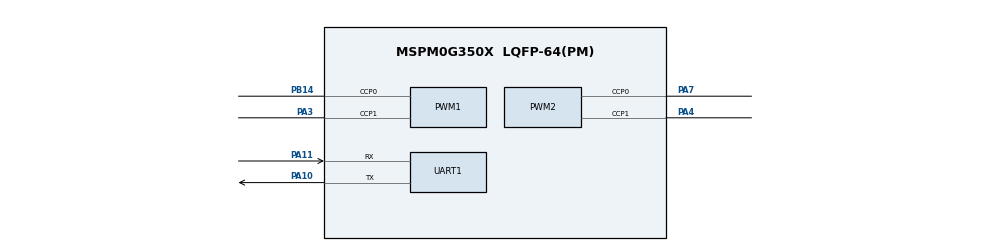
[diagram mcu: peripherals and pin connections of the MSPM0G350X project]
/**
 * @cliArgs --device "MSPM0G350X" --package "LQFP-64(PM)" --part "Default" --product "mspm0_sdk@2.01.00.03"
 * @versions {"tool":"1.20.0+3587"}
 */

/**
 * Import the modules used in this configuration.
 */
const Board         = scripting.addModule("/ti/driverlib/Board");
const GPIO          = scripting.addModule("/ti/driverlib/GPIO", {}, false);
const GPIO1         = GPIO.addInstance();
const GPIO2         = GPIO.addInstance();
const PWM           = scripting.addModule("/ti/driverlib/PWM", {}, false);
const PWM1          = PWM.addInstance();
const PWM2          = PWM.addInstance();
const SYSCTL        = scripting.addModule("/ti/driverlib/SYSCTL");
const TIMER         = scripting.addModule("/ti/driverlib/TIMER", {}, false);
const TIMER1        = TIMER.addInstance();
const UART          = scripting.addModule("/ti/driverlib/UART", {}, false);
const UART1         = UART.addInstance();
const ProjectConfig = scripting.addModule("/ti/project_config/ProjectConfig");

/**
 * Write custom configuration values to the imported modules.
 */

GPIO1.$name                          = "PCA9555";
GPIO1.associatedPins.create(2);
GPIO1.associatedPins[0].assignedPort = "PORTA";
GPIO1.associatedPins[0].assignedPin  = "0";
GPIO1.associatedPins[0].$name        = "SCL1";
GPIO1.associatedPins[1].assignedPort = "PORTA";
GPIO1.associatedPins[1].assignedPin  = "1";
GPIO1.associatedPins[1].$name        = "SDA1";

GPIO2.$name                          = "OLED";
GPIO2.associatedPins.create(2);
GPIO2.associatedPins[0].$name        = "SCL2";
GPIO2.associatedPins[0].assignedPort = "PORTB";
GPIO2.associatedPins[0].assignedPin  = "2";
GPIO2.associatedPins[1].$name        = "SDA2";
GPIO2.associatedPins[1].assignedPort = "PORTB";
GPIO2.associatedPins[1].assignedPin  = "3";

PWM1.$name                              = "Motor_PWM1";
PWM1.timerStartTimer                    = true;
PWM1.pwmMode                            = "EDGE_ALIGN_UP";
PWM1.timerCount                         = 3000;
PWM1.clockDivider                       = 8;
PWM1.peripheral.$assign                 = "TIMA0";
PWM1.peripheral.ccp0Pin.$assign         = "PB14";
PWM1.peripheral.ccp1Pin.$assign         = "PA3";
PWM1.PWM_CHANNEL_0.$name                = "ti_driverlib_pwm_PWMTimerCC0";
PWM1.PWM_CHANNEL_1.$name                = "ti_driverlib_pwm_PWMTimerCC1";
PWM1.ccp0PinConfig.$name                = "ti_driverlib_gpio_GPIOPinGeneric0";
PWM1.ccp0PinConfig.direction            = scripting.forceWrite("OUTPUT");
PWM1.ccp0PinConfig.hideOutputInversion  = scripting.forceWrite(false);
PWM1.ccp0PinConfig.onlyInternalResistor = scripting.forceWrite(false);
PWM1.ccp0PinConfig.passedPeripheralType = scripting.forceWrite("Digital");
PWM1.ccp1PinConfig.$name                = "ti_driverlib_gpio_GPIOPinGeneric1";
PWM1.ccp1PinConfig.direction            = scripting.forceWrite("OUTPUT");
PWM1.ccp1PinConfig.hideOutputInversion  = scripting.forceWrite(false);
PWM1.ccp1PinConfig.onlyInternalResistor = scripting.forceWrite(false);
PWM1.ccp1PinConfig.passedPeripheralType = scripting.forceWrite("Digital");

PWM2.timerCount                         = 3000;
PWM2.clockDivider                       = 8;
PWM2.$name                              = "Motor_PWM2";
PWM2.timerStartTimer                    = true;
PWM2.pwmMode                            = "EDGE_ALIGN_UP";
PWM2.peripheral.$assign                 = "TIMG8";
PWM2.peripheral.ccp0Pin.$assign         = "PA7";
PWM2.peripheral.ccp1Pin.$assign         = "PA4";
PWM2.PWM_CHANNEL_0.$name                = "ti_driverlib_pwm_PWMTimerCC2";
PWM2.PWM_CHANNEL_1.$name                = "ti_driverlib_pwm_PWMTimerCC3";
PWM2.ccp0PinConfig.$name                = "ti_driverlib_gpio_GPIOPinGeneric2";
PWM2.ccp0PinConfig.direction            = scripting.forceWrite("OUTPUT");
PWM2.ccp0PinConfig.hideOutputInversion  = scripting.forceWrite(false);
PWM2.ccp0PinConfig.onlyInternalResistor = scripting.forceWrite(false);
PWM2.ccp0PinConfig.passedPeripheralType = scripting.forceWrite("Digital");
PWM2.ccp1PinConfig.$name                = "ti_driverlib_gpio_GPIOPinGeneric3";
PWM2.ccp1PinConfig.direction            = scripting.forceWrite("OUTPUT");
PWM2.ccp1PinConfig.hideOutputInversion  = scripting.forceWrite(false);
PWM2.ccp1PinConfig.onlyInternalResistor = scripting.forceWrite(false);
PWM2.ccp1PinConfig.passedPeripheralType = scripting.forceWrite("Digital");

SYSCTL.clockTreeEn = true;

TIMER1.$name              = "TIMER_delay";
TIMER1.timerClkDiv        = 8;
TIMER1.interrupts         = ["ZERO"];
TIMER1.timerPeriod        = "0.01ms";
TIMER1.timerClkPrescale   = 99;
TIMER1.peripheral.$assign = "TIMA1";

UART1.$name                            = "UART_DEBUG";
UART1.targetBaudRate                   = 115200;
UART1.peripheral.$assign               = "UART0";
UART1.peripheral.rxPin.$assign         = "PA11";
UART1.peripheral.txPin.$assign         = "PA10";
UART1.txPinConfig.direction            = scripting.forceWrite("OUTPUT");
UART1.txPinConfig.hideOutputInversion  = scripting.forceWrite(false);
UART1.txPinConfig.onlyInternalResistor = scripting.forceWrite(false);
UART1.txPinConfig.passedPeripheralType = scripting.forceWrite("Digital");
UART1.txPinConfig.$name                = "ti_driverlib_gpio_GPIOPinGeneric7";
UART1.rxPinConfig.hideOutputInversion  = scripting.forceWrite(false);
UART1.rxPinConfig.onlyInternalResistor = scripting.forceWrite(false);
UART1.rxPinConfig.passedPeripheralType = scripting.forceWrite("Digital");
UART1.rxPinConfig.$name                = "ti_driverlib_gpio_GPIOPinGeneric8";

ProjectConfig.genDisable = true;
scripting.suppress("Project Configuration File generation is disabled for this project\\. SysConfig Project Migration is not currently supported for this project\\.", ProjectConfig);

/**
 * Pinmux solution for unlocked pins/peripherals. This ensures that minor changes to the automatic solver in a future
 * version of the tool will not impact the pinmux you originally saw.  These lines can be completely deleted in order to
 * re-solve from scratch.
 */
Board.peripheral.$suggestSolution            = "DEBUGSS";
Board.peripheral.swclkPin.$suggestSolution   = "PA20";
Board.peripheral.swdioPin.$suggestSolution   = "PA19";
GPIO1.associatedPins[0].pin.$suggestSolution = "PA0";
GPIO1.associatedPins[1].pin.$suggestSolution = "PA1";
GPIO2.associatedPins[0].pin.$suggestSolution = "PB2";
GPIO2.associatedPins[1].pin.$suggestSolution = "PB3";
